# STM32L053x register map
File version: 1.0
Registers are 32-bit, read-write, reset 0x0 unless marked. A register's access mark holds for its fields unless they carry their own. Offsets are from the block's base; lines under a group give offsets from that group; [hi:lo] are bit positions; {n}, {i} and the like mark numbered series; 'fields as' and 'values as' point back to an identical list; <NAME> marks a mode.

## Memory map
0x40000000 TIM2 size 0x400 — General-purpose-timers
0x40001000 TIM6 size 0x400 — Basic-timers
0x40002400 LCD size 0x400 — Liquid crystal display controller
0x40002800 RTC size 0x400 — Real-time clock
0x40002C00 WWDG size 0x400 — System window watchdog
0x40003000 IWDG size 0x400 — Independent watchdog
0x40003800 SPI2 size 0x400
0x40004400 USART2 size 0x400
0x40004800 LPUSART1 size 0x400 — Universal synchronous asynchronous receiver transmitter
0x40005400 I2C1 size 0x400 — Inter-integrated circuit
0x40005800 I2C2 size 0x400
0x40005C00 USB_FS size 0x400 — Universal serial bus full-speed device interface
0x40006C00 CRS size 0x400 — Clock recovery system
0x40007000 PWR size 0x400 — Power control
0x40007400 DAC size 0x400 — Digital-to-analog converter
0x40007C00 LPTIM size 0x400 — Low power timer
0x40010000 SYSCFG size 0x400 — System configuration controller
0x40010018 COMP size 0x400 — Comparator
0x40010400 EXTI size 0x400 — External interrupt/event controller
0x40010800 TIM21 size 0x400 — General-purpose-timers
0x40011400 TIM22 size 0x400 — General-purpose-timers
0x40011C00 Firewall size 0x400
0x40012400 ADC size 0x400 — Analog-to-digital converter
0x40013000 SPI1 size 0x400 — Serial peripheral interface
0x40013800 USART1 size 0x400 — Universal synchronous asynchronous receiver transmitter
0x40015800 DBGMCU size 0x400 — Debug support
0x40020000 DMA1 size 0x400 — Direct memory access controller
0x40021000 RCC size 0x400 — Reset and clock control
0x40022000 Flash size 0x400
0x40023000 CRC size 0x400 — Cyclic redundancy check calculation unit
0x40024000 TSC size 0x400 — Touch sensing controller
0x40025000 RNG size 0x400 — Random number generator
0x50000000 GPIOA size 0x400 — General-purpose I/Os
0x50000400 GPIOB size 0x400 — General-purpose I/Os
0x50000800 GPIOC size 0x400
0x50000C00 GPIOD size 0x400
0x50001C00 GPIOH size 0x400
0xE000E100 NVIC size 0x33D — Nested Vectored Interrupt Controller

## Interrupts
0 WWDG — Window Watchdog interrupt
1 PVD (PWR) — PVD through EXTI line detection
2 RTC — RTC global interrupt
3 FLASH (Flash) — Flash global interrupt
4 RCC — RCC global interrupt
5 EXTI0_1 (EXTI) — EXTI Line[1:0] interrupts
6 EXTI2_3 (EXTI) — EXTI Line[3:2] interrupts
7 EXTI4_15 (EXTI) — EXTI Line15 and EXTI4 interrupts
8 TSC — Touch sensing interrupt
9 DMA1_Channel1 (DMA1) — DMA1 Channel1 global interrupt
10 DMA1_Channel2_3 (DMA1) — DMA1 Channel2 and 3 interrupts
11 DMA1_Channel4_7 (DMA1) — DMA1 Channel4 to 7 interrupts
12 ADC_COMP (ADC) — ADC and comparator 1 and 2
13 LPTIM1 (LPTIM) — LPTIMER1 interrupt through EXTI29
15 TIM2 — TIM2 global interrupt
17 TIM6_DAC (TIM6) — TIM6 global interrupt and DAC
20 TIM21 — TIMER21 global interrupt
22 TIM22 — TIMER22 global interrupt
23 I2C1 — I2C1 global interrupt
24 I2C2 — I2C2 global interrupt
25 SPI1 — SPI1_global_interrupt
26 SPI2 — SPI2 global interrupt
27 USART1 — USART1 global interrupt
28 USART2 — USART2 global interrupt
29 RNG_LPUART1 (EXTI) — RNG global interrupt and LPUART1 global interrupt through
30 LCD — LCD global interrupt
31 USB (USB_FS) — USB event interrupt through EXTI18

## DAC — Digital-to-analog converter
Base 0x40007400
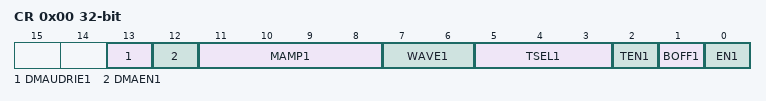
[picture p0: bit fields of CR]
0x00 CR — control register
  [13] DMAUDRIE1 — DAC channel1 DMA Underrun Interrupt enable
  [12] DMAEN1 — DAC channel1 DMA enable
  [11:8] MAMP1 — DAC channel1 mask/amplitude selector
  [7:6] WAVE1 — DAC channel1 noise/triangle wave generation enable
  [5:3] TSEL1 — DAC channel1 trigger selection
  [2] TEN1 — DAC channel1 trigger enable
  [1] BOFF1 — DAC channel1 output buffer disable
  [0] EN1 — DAC channel1 enable
0x04 SWTRIGR wo — software trigger register
  [0] SWTRIG1 — DAC channel1 software trigger
0x08 DHR12R1 — channel1 12-bit right-aligned data holding register
  [11:0] DACC1DHR — DAC channel1 12-bit right-aligned data
0x0C DHR12L1 — channel1 12-bit left-aligned data holding register
  [15:4] DACC1DHR — DAC channel1 12-bit left-aligned data
0x10 DHR8R1 — channel1 8-bit right-aligned data holding register
  [7:0] DACC1DHR — DAC channel1 8-bit right-aligned data
0x2C DOR1 ro — channel1 data output register
  [11:0] DACC1DOR — DAC channel1 data output
0x34 SR rw-once — status register
  [13] DMAUDR1 — DAC channel1 DMA underrun flag
